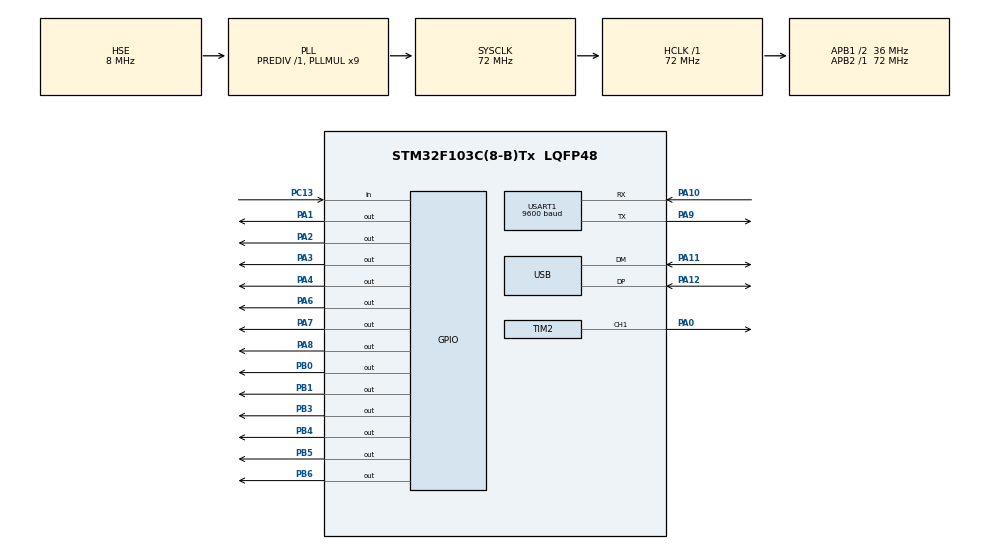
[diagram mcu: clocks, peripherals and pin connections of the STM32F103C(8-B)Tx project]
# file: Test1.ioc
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Mcu.Family=STM32F1
Mcu.Name=STM32F103C(8-B)Tx
Mcu.Package=LQFP48
NVIC.PriorityGroup=NVIC_PRIORITYGROUP_4
NVIC.TIM2_IRQn=true\:0\:0\:false\:false\:true\:true\:true\:true
NVIC.USART1_IRQn=true\:0\:0\:false\:false\:true\:true\:true\:true
NVIC.USB_LP_CAN1_RX0_IRQn=true\:0\:0\:false\:false\:true\:false\:true\:true
PA0-WKUP.Signal=S_TIM2_CH1_ETR
PA1.Signal=GPIO_Output
PA10.Mode=Asynchronous
PA10.Signal=USART1_RX
PA11.Mode=Device
PA11.Signal=USB_DM
PA12.Mode=Device
PA12.Signal=USB_DP
PA2.Signal=GPIO_Output
PA3.Signal=GPIO_Output
PA4.Signal=GPIO_Output
PA6.Signal=GPIO_Output
PA7.Signal=GPIO_Output
PA8.Signal=GPIO_Output
PA9.Mode=Asynchronous
PA9.Signal=USART1_TX
PB0.Signal=GPIO_Output
PB1.Signal=GPIO_Output
PB3.Signal=GPIO_Output
PB4.Signal=GPIO_Output
PB5.Signal=GPIO_Output
PB6.Signal=GPIO_Output
PC13-TAMPER-RTC.GPIO_PuPd=GPIO_PULLUP
PC13-TAMPER-RTC.Signal=GPIO_Input
PD0-OSC_IN.Mode=HSE-External-Oscillator
PD0-OSC_IN.Signal=RCC_OSC_IN
PD1-OSC_OUT.Mode=HSE-External-Oscillator
PD1-OSC_OUT.Signal=RCC_OSC_OUT
ProjectManager.HeapSize=0x200
ProjectManager.StackSize=0x400
ProjectManager.TargetToolchain=Makefile
RCC.AHBFreq_Value=72000000
RCC.APB1CLKDivider=RCC_HCLK_DIV2
RCC.APB1Freq_Value=36000000
RCC.APB1TimFreq_Value=72000000
RCC.APB2Freq_Value=72000000
RCC.APB2TimFreq_Value=72000000
RCC.HCLKFreq_Value=72000000
RCC.PLLMUL=RCC_PLL_MUL9
RCC.PLLSourceVirtual=RCC_PLLSOURCE_HSE
RCC.SYSCLKFreq_VALUE=72000000
RCC.SYSCLKSource=RCC_SYSCLKSOURCE_PLLCLK
RCC.USBFreq_Value=48000000
RCC.USBPrescaler=RCC_USBCLKSOURCE_PLL_DIV1_5
SH.S_TIM2_CH1_ETR.0=TIM2_CH1,Output Compare1 CH1
TIM2.Channel-Output\ Compare1\ CH1=TIM_CHANNEL_1
TIM2.Period=100
TIM2.Prescaler=7199
USART1.BaudRate=9600
USART1.VirtualMode=VM_ASYNC
USB_DEVICE.CLASS_NAME_FS=CDC
USB_DEVICE.VirtualMode=Cdc
USB_DEVICE.VirtualModeFS=Cdc_FS
VP_SYS_VS_ND.Mode=No_Debug
VP_TIM2_VS_ClockSourceINT.Mode=Internal
VP_USB_DEVICE_VS_USB_DEVICE_CDC_FS.Mode=CDC_FS
board=custom

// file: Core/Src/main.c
/* USER CODE BEGIN Header */
/**
  **
  * @file           : main.c
  * @brief          : Main program body
  **
  * @attention
  *
  * Copyright (c) 2024 STMicroelectronics.
  * All rights reserved.
  *
  * This software is licensed under terms that can be found in the LICENSE file
  * in the root directory of this software component.
  * If no LICENSE file comes with this software, it is provided AS-IS.
  *
  **
  */
/* USER CODE END Header */
#include "main.h"
#include "usb_device.h"

/* USER CODE BEGIN Includes */
#include <stdio.h>      // add for printf
#include <stdlib.h>
#include <string.h>
#include <time.h>       // add for srand() and rand()
/* USER CODE END Includes */

TIM_HandleTypeDef htim2;
GPIO_InitTypeDef GPIO_InitStruct = {0};
uint8_t led_index = 0;
UART_HandleTypeDef huart1;

void SystemClock_Config(void);
static void MX_GPIO_Init(void);
static void MX_USART1_UART_Init(void);
static void MX_TIM2_Init(void);

/* USER CODE BEGIN 0 */

#ifdef GNUC
#define PUTCHAR_PROTOTYPE int __io_putchar(int ch)
#else
#define PUTCHAR_PROTOTYPE int fputc(int ch, FILE *f)
#endif

/**
  * @brief  Retargets the C library printf function to the USART.
  * @param  None
  * @retval None
  */

/* Timer2 Interrupt Service Routine: Blinks LEDs */

/* USER CODE END 0 */

void customDelay(uint32_t milliseconds)
{
  uint32_t start = HAL_GetTick();
  while ((HAL_GetTick() - start) < milliseconds) {}
}

int main(void)
{
  HAL_Init();
  SystemClock_Config();
  MX_GPIO_Init();
  MX_TIM2_Init();
  MX_USART1_UART_Init();

  HAL_TIM_Base_Start_IT(&htim2);

  // Initialize random number generator
  srand(time(NULL));

  while (1)
  {
    // Turn off all LEDs
    HAL_GPIO_WritePin(GPIOA, GPIO_PIN_2 | GPIO_PIN_3 | GPIO_PIN_4 | GPIO_PIN_1 | GPIO_PIN_6 | GPIO_PIN_7, GPIO_PIN_RESET);
    HAL_GPIO_WritePin(GPIOB, GPIO_PIN_0 | GPIO_PIN_1 | GPIO_PIN_3 | GPIO_PIN_4 | GPIO_PIN_5 | GPIO_PIN_6, GPIO_PIN_RESET);

    // Ruleta se oprește după un timp aleatoriu între 3 și 5 secunde
    uint32_t stopTime = rand() % 3000 + 3000; // valori între 3000 și 5000 milisecunde

    uint32_t currentTime = 0;
    while (currentTime < stopTime)
    {
      // Se așteaptă 100 milisecunde între fiecare schimbare de LED-uri
      for (int i = 0; i < 8; i++) // Iterate through PA0 to PA7
      {
        // Turn on the current LED on port A
        HAL_GPIO_WritePin(GPIOA, GPIO_PIN_1 << i, GPIO_PIN_SET);
        customDelay(100); // Așteaptă pentru o durată scurtă

        // Turn off the current LED on port A
        HAL_GPIO_WritePin(GPIOA, GPIO_PIN_1 << i, GPIO_PIN_RESET);
      }

      for (int i = 3; i <=6; i++) // Iterate through PB0 to PB3
      {
        // Turn on the current LED on port B
        HAL_GPIO_WritePin(GPIOB, GPIO_PIN_3 << i, GPIO_PIN_SET);
        customDelay(100); // Așteaptă pentru o durată scurtă

        // Turn off the current LED on port B
        HAL_GPIO_WritePin(GPIOB, GPIO_PIN_3 << i, GPIO_PIN_RESET);
      }

      currentTime += 800; // Adaugă timpul petrecut într-un ciclu complet al ruletei
    }

    // Ruleta se oprește la un LED aleatoriu
    int randomLed = rand() % 10; // Generează un număr aleatoriu între 0 și 9
    if (randomLed < 6)
    {
      // Oprire pe un LED de pe portul A
      HAL_GPIO_WritePin(GPIOA, GPIO_PIN_1 << randomLed, GPIO_PIN_SET);
    }
    else
    {
      // Oprire pe un LED de pe portul B
      HAL_GPIO_WritePin(GPIOB, GPIO_PIN_3 << (randomLed - 6), GPIO_PIN_SET);
    }

    // Așteaptă pentru o perioadă scurtă înainte de a începe următoarea rotație a ruletei
    HAL_Delay(2000); // Așteaptă 2 secunde între rotațiile ruletei
  }
}

void SystemClock_Config(void)
{
  RCC_OscInitTypeDef RCC_OscInitStruct = {0};
  RCC_ClkInitTypeDef RCC_ClkInitStruct = {0};
  RCC_PeriphCLKInitTypeDef PeriphClkInit = {0};

  RCC_OscInitStruct.OscillatorType = RCC_OSCILLATORTYPE_HSE;
  RCC_OscInitStruct.HSEState = RCC_HSE_ON;
  RCC_OscInitStruct.HSEPredivValue = RCC_HSE_PREDIV_DIV1;
  RCC_OscInitStruct.HSIState = RCC_HSI_ON;
  RCC_OscInitStruct.PLL.PLLState = RCC_PLL_ON;
  RCC_OscInitStruct.PLL.PLLSource = RCC_PLLSOURCE_HSE;
  RCC_OscInitStruct.PLL.PLLMUL = RCC_PLL_MUL9;
  if (HAL_RCC_OscConfig(&RCC_OscInitStruct) != HAL_OK)
  {
    Error_Handler();
  }

  RCC_ClkInitStruct.ClockType = RCC_CLOCKTYPE_HCLK | RCC_CLOCKTYPE_SYSCLK | RCC_CLOCKTYPE_PCLK1 | RCC_CLOCKTYPE_PCLK2;
  RCC_ClkInitStruct.SYSCLKSource = RCC_SYSCLKSOURCE_PLLCLK;
  RCC_ClkInitStruct.AHBCLKDivider = RCC_SYSCLK_DIV1;
  RCC_ClkInitStruct.APB1CLKDivider = RCC_HCLK_DIV2;
  RCC_ClkInitStruct.APB2CLKDivider = RCC_HCLK_DIV1;
  if (HAL_RCC_ClockConfig(&RCC_ClkInitStruct, FLASH_LATENCY_2) != HAL_OK)
  {
    Error_Handler();
  }
  PeriphClkInit.PeriphClockSelection = RCC_PERIPHCLK_USB;
  PeriphClkInit.UsbClockSelection = RCC_USBCLKSOURCE_PLL_DIV1_5;
  if (HAL_RCCEx_PeriphCLKConfig(&PeriphClkInit) != HAL_OK)
  {
    Error_Handler();
  }
}

void MX_TIM2_Init(void)
{
  TIM_ClockConfigTypeDef sClockSourceConfig = {0};
  TIM_MasterConfigTypeDef sMasterConfig = {0};

  htim2.Instance = TIM2;
  htim2.Init.Prescaler = 7199;
  htim2.Init.CounterMode = TIM_COUNTERMODE_UP;
  htim2.Init.Period = 100;
  htim2.Init.ClockDivision = TIM_CLOCKDIVISION_DIV1;
  htim2.Init.AutoReloadPreload = TIM_AUTORELOAD_PRELOAD_DISABLE;
  if (HAL_TIM_Base_Init(&htim2) != HAL_OK)
  {
    Error_Handler();
  }
  sClockSourceConfig.ClockSource = TIM_CLOCKSOURCE_INTERNAL;
  if (HAL_TIM_ConfigClockSource(&htim2, &sClockSourceConfig) != HAL_OK)
  {
    Error_Handler();
  }
  sMasterConfig.MasterOutputTrigger = TIM_TRGO_RESET;
  sMasterConfig.MasterSlaveMode = TIM_MASTERSLAVEMODE_DISABLE;
  if (HAL_TIMEx_MasterConfigSynchronization(&htim2, &sMasterConfig) != HAL_OK)
  {
    Error_Handler();
  }
}

void MX_USART1_UART_Init(void)
{
  huart1.Instance = USART1;
  huart1.Init.BaudRate = 9600;
  huart1.Init.WordLength = UART_WORDLENGTH_8B;
  huart1.Init.StopBits = UART_STOPBITS_1;
  huart1.Init.Parity = UART_PARITY_NONE;
  huart1.Init.Mode = UART_MODE_TX_RX;
  huart1.Init.HwFlowCtl = UART_HWCONTROL_NONE;
  huart1.Init.OverSampling = UART_OVERSAMPLING_16;
  if (HAL_UART_Init(&huart1) != HAL_OK)
  {
    Error_Handler();
  }
}

void MX_GPIO_Init(void)
{
  GPIO_InitTypeDef GPIO_InitStruct = {0};

  __HAL_RCC_GPIOC_CLK_ENABLE();
  __HAL_RCC_GPIOD_CLK_ENABLE();
  __HAL_RCC_GPIOA_CLK_ENABLE();
  __HAL_RCC_GPIOB_CLK_ENABLE();

  HAL_GPIO_WritePin(GPIOA, GPIO_PIN_2 | GPIO_PIN_3 | GPIO_PIN_4 | GPIO_PIN_1 | GPIO_PIN_6 | GPIO_PIN_7, GPIO_PIN_RESET);
  HAL_GPIO_WritePin(GPIOB, GPIO_PIN_0 | GPIO_PIN_1 | GPIO_PIN_3 | GPIO_PIN_4 | GPIO_PIN_5 | GPIO_PIN_6, GPIO_PIN_RESET);

  GPIO_InitStruct.Pin = GPIO_PIN_13;
  GPIO_InitStruct.Mode = GPIO_MODE_INPUT;
  GPIO_InitStruct.Pull = GPIO_PULLUP;
  HAL_GPIO_Init(GPIOC, &GPIO_InitStruct);

  GPIO_InitStruct.Pin = GPIO_PIN_2 | GPIO_PIN_3 | GPIO_PIN_4 | GPIO_PIN_1 | GPIO_PIN_6 | GPIO_PIN_7;
  GPIO_InitStruct.Mode = GPIO_MODE_OUTPUT_PP;
  GPIO_InitStruct.Pull = GPIO_NOPULL;
  GPIO_InitStruct.Speed = GPIO_SPEED_FREQ_LOW;
  HAL_GPIO_Init(GPIOA, &GPIO_InitStruct);

  GPIO_InitStruct.Pin = GPIO_PIN_1;
  GPIO_InitStruct.Mode = GPIO_MODE_INPUT;
  GPIO_InitStruct.Pull = GPIO_NOPULL;
  HAL_GPIO_Init(GPIOA, &GPIO_InitStruct);

  GPIO_InitStruct.Pin = GPIO_PIN_0 | GPIO_PIN_1 | GPIO_PIN_3 | GPIO_PIN_4 | GPIO_PIN_5 | GPIO_PIN_6;
  GPIO_InitStruct.Mode = GPIO_MODE_OUTPUT_PP;
  GPIO_InitStruct.Pull = GPIO_NOPULL;
  GPIO_InitStruct.Speed = GPIO_SPEED_FREQ_LOW;
  HAL_GPIO_Init(GPIOB, &GPIO_InitStruct);
}

void Error_Handler(void)
{
  __disable_irq();
  while (1)
  {
  }
}
